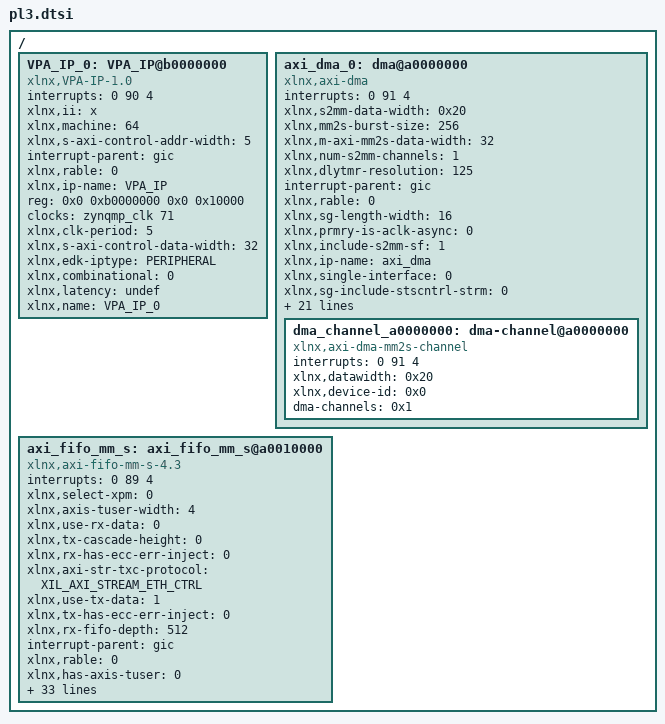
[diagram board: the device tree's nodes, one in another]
/dts-v1/;
/plugin/;

/ {
   fragment@0 {
        target-path = "/";
        __overlay__ {        
            VPA_IP_0: VPA_IP@b0000000 {
		    	interrupts = < 0 90 4 >;
		    	compatible = "xlnx,VPA-IP-1.0";
		    	xlnx,ii = "x";
		    	xlnx,machine = <64>;
		    	xlnx,s-axi-control-addr-width = <5>;
		    	interrupt-parent = <&gic>;
		    	xlnx,rable = <0>;
		    	xlnx,ip-name = "VPA_IP";
		    	reg = <0x0 0xb0000000 0x0 0x10000>;
		    	clocks = <&zynqmp_clk 71>;
		    	xlnx,clk-period = <5>;
		    	xlnx,s-axi-control-data-width = <32>;
		    	xlnx,edk-iptype = "PERIPHERAL";
		    	status = "okay";
		    	clock-names = "ap_clk";
		    	interrupt-names = "interrupt";
		    	xlnx,combinational = <0>;
		    	xlnx,latency = "undef";
		    	xlnx,name = "VPA_IP_0";
		    };
		    axi_dma_0: dma@a0000000 {
		    	interrupts = < 0 91 4 >;
		    	compatible = "xlnx,axi-dma";
		    	xlnx,s2mm-data-width = <0x20>;
		    	xlnx,mm2s-burst-size = <256>;
		    	xlnx,m-axi-mm2s-data-width = <32>;
		    	xlnx,num-s2mm-channels = <1>;
		    	xlnx,dlytmr-resolution = <125>;
		    	interrupt-parent = <&gic>;
		    	xlnx,rable = <0>;
		    	xlnx,sg-length-width = <16>;
		    	xlnx,prmry-is-aclk-async = <0>;
		    	xlnx,include-s2mm-sf = <1>;
		    	#dma-cells = <1>;
		    	xlnx,ip-name = "axi_dma";
		    	xlnx,single-interface = <0>;
		    	xlnx,sg-include-stscntrl-strm = <0>;
		    	xlnx,include-s2mm-dre = <0>;
		    	reg = <0x0 0xa0000000 0x0 0x10000>;
		    	xlnx,addr-width = <32>;
		    	xlnx,include-s2mm = <0>;
		    	clocks = <&zynqmp_clk 71>, <&zynqmp_clk 71>;
		    	xlnx,s-axis-s2mm-tdata-width = <32>;
		    	xlnx,micro-dma = <0>;
		    	xlnx,increase-throughput = <0>;
		    	xlnx,mm2s-data-width = <0x20>;
		    	xlnx,addrwidth = <0x20>;
		    	xlnx,sg-use-stsapp-length = <0>;
		    	xlnx,m-axis-mm2s-tdata-width = <32>;
		    	xlnx,edk-iptype = "PERIPHERAL";
		    	xlnx,s2mm-burst-size = <16>;
		    	xlnx,m-axi-s2mm-data-width = <32>;
		    	xlnx,num-mm2s-channels = <1>;
		    	xlnx,enable-multi-channel = <0>;
		    	status = "okay";
		    	xlnx,include-mm2s-sf = <1>;
		    	clock-names = "s_axi_lite_aclk" , "m_axi_mm2s_aclk";
		    	interrupt-names = "mm2s_introut";
		    	xlnx,include-mm2s = <1>;
		    	xlnx,include-mm2s-dre = <0>;
		    	xlnx,name = "axi_dma_0";
		    	dma_channel_a0000000: dma-channel@a0000000 {
		    		interrupts = <0 91 4>;
		    		xlnx,datawidth = <0x20>;
		    		xlnx,device-id = <0x0>;
		    		compatible = "xlnx,axi-dma-mm2s-channel";
		    		dma-channels = <0x1>;
		    	};
		    };
		    axi_fifo_mm_s: axi_fifo_mm_s@a0010000 {
		    	interrupts = < 0 89 4 >;
		    	xlnx,select-xpm = <0>;
		    	xlnx,axis-tuser-width = <4>;
		    	compatible = "xlnx,axi-fifo-mm-s-4.3";
		    	xlnx,use-rx-data = <0>;
		    	xlnx,tx-cascade-height = <0>;
		    	xlnx,rx-has-ecc-err-inject = <0>;
		    	xlnx,axi-str-txc-protocol = "XIL_AXI_STREAM_ETH_CTRL";
		    	xlnx,use-tx-data = <1>;
		    	xlnx,tx-has-ecc-err-inject = <0>;
		    	xlnx,rx-fifo-depth = <512>;
		    	interrupt-parent = <&gic>;
		    	xlnx,rable = <0>;
		    	xlnx,has-axis-tuser = <0>;
		    	xlnx,tx-fifo-depth = <512>;
		    	xlnx,rx-fifo-pe-threshold = <5>;
		    	xlnx,data-interface-type = <1>;
		    	xlnx,ip-name = "axi_fifo_mm_s";
		    	xlnx,use-tx-ctrl = <0>;
		    	xlnx,rx-fifo-pf-threshold = <507>;
		    	xlnx,axis-tid-width = <4>;
		    	reg = <0x0 0xa0010000 0x0 0x1000 0x0 0xa0012000 0x0 0x2000>;
		    	clocks = <&zynqmp_clk 71>;
		    	xlnx,tx-fifo-pe-threshold = <5>;
		    	xlnx,tx-fifo-pf-threshold = <507>;
		    	xlnx,s-axi4-data-width = <32>;
		    	xlnx,has-axis-tstrb = <0>;
		    	xlnx,axi-str-rxd-protocol = "XIL_AXI_STREAM_ETH_DATA";
		    	xlnx,use-rx-cut-through = <0>;
		    	xlnx,axi-str-rxd-tdata-width = <32>;
		    	xlnx,axis-tdest-width = <4>;
		    	xlnx,edk-iptype = "PERIPHERAL";
		    	xlnx,has-axis-tkeep = <0>;
		    	xlnx,has-axis-tid = <0>;
		    	xlnx,axi-str-txc-tdata-width = <32>;
		    	xlnx,axi-str-txd-protocol = "XIL_AXI_STREAM_ETH_DATA";
		    	xlnx,use-tx-cut-through = <1>;
		    	xlnx,axi-str-txd-tdata-width = <32>;
		    	xlnx,rx-enable-ecc = <0>;
		    	status = "okay";
		    	clock-names = "s_axi_aclk";
		    	xlnx,has-axis-tdest = <0>;
		    	interrupt-names = "interrupt";
		    	xlnx,tx-enable-ecc = <0>;
		    	xlnx,s-axi-id-width = <16>;
		    	xlnx,rx-cascade-height = <0>;
		    	xlnx,name = "axi_fifo_mm_s";
		    };
        };
    };
};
